# EFR32MG24A111F1536GM48 register map
Vendor: Silicon Labs; Series: EFR32; File version: B
Registers are 32-bit, read-write, reset 0x0 unless marked. A register's access mark holds for its fields unless they carry their own. Offsets are from the block's base; [hi:lo] are bit positions; {n}, {i} and the like mark numbered series; 'fields as' and 'values as' point back to an identical list.

## SYNTH_S — SYNTH_S Registers
Base 0xA8018000
Same registers: SYNTH_NS 0xB8018000
0x00 IPVERSION ro reset 0x2
0x04 EN
  [0] EN — Enable peripheral clock to this module
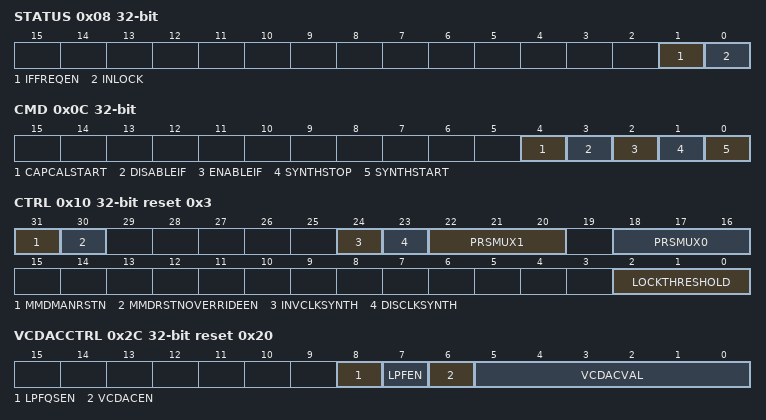
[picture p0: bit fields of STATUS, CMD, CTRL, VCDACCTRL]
0x08 STATUS ro
  [1] IFFREQEN — Synthesizer IF frequency enable status
  [0] INLOCK — RF Synthesizer in Lock
0x0C CMD wo
  [4] CAPCALSTART — Start VCO capacitor array calibration
  [3] DISABLEIF — Disable the synthesizer IF frequency
  [2] ENABLEIF — Enable the synthesizer IF frequency
  [1] SYNTHSTOP — Stops the RF synthesizer
  [0] SYNTHSTART — Starts the RF synthesizer
0x10 CTRL reset 0x3
  [31] MMDMANRSTN — Manual MMD reset
    0=RESET (Reset MMD and DSM logic); 1=NORESET (Allow MMD and DSM to run)
  [30] MMDRSTNOVERRIDEEN — Enable MMD reset override
    0=DISABLE (Disable MMD reset override); 1=ENABLE (Enable MMD reset override)
  [24] INVCLKSYNTH — Invert clk_synth
    0=NO (Do not invert clk_synth); 1=YES (Invert clk_synth)
  [23] DISCLKSYNTH — Disable clk_synth
    0=ENABLE (Enable clk_synth); 1=DISABLE (Disable clk_synth)
  [22:20] PRSMUX1 — PRS output mux 1 selector
    0=DISABLED (PRS output 1 is disabled); 1=AUXINLOCK (Obsolete. read returns 0.); 2=REF_IS_LEADING (Disabled. Read returns 0.); 3=FPLL (Divided PLL clock); 4=VCCMP_LOW (VCO voltage low detected); 5=MMD_PRESCALER_RESET_N (MMD prescaler reset, active low); 6=CLK_SYNTH_DIV2 (MMD next denom output, corresponding to the delta-sigma clock, divided by 2.)
  [18:16] PRSMUX0 — PRS output mux 0 selector
    0=DISABLED (PRS output 0 is disabled); 1=INLOCK (Synthesizer is in lock); 2=LOCK_WINDOW (PLL Lock Window, sampled by PFD); 3=FPLL (Divided PLL clock); 4=VCCMP_HI (VCO voltage high detected); 5=VCO_AMPLITUDE_OK (Obsolete. Read returns 1.); 6=VCO_DET_OUT_D (Obsolete. Read returns 0.)
  [2:0] LOCKTHRESHOLD — Frequency synthesizer lock threshold
0x2C VCDACCTRL reset 0x20
  [8] LPFQSEN — LPF Quickstart Control
    0=DISABLE (Disable LPF); 1=ENABLE (Enable LPF)
  [7] LPFEN — LPF Enable Control
    0=DISABLE (Disable LPF); 1=ENABLE (Enable LPF)
  [6] VCDACEN — Enable VCDAC
    0=DISABLE (VC DAC disabled); 1=ENABLE (VC DAC enabled)
  [5:0] VCDACVAL — Control voltage to VCO
0x34 FREQ
  [27:0] FREQ — RF Carrier Frequency.
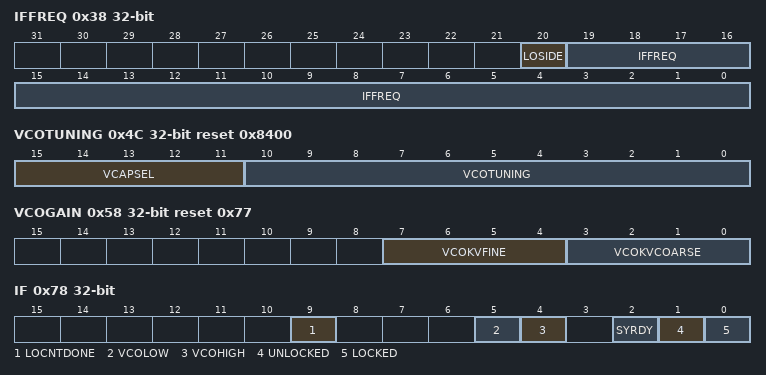
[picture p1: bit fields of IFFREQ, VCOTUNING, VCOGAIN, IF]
0x38 IFFREQ
  [20] LOSIDE — Configure LO in receive
    0=LOW (The local oscillator (LO) is lower in frequency than the receive RF channel. In MODEM_MIXCTRL the ANAMIXMODE field must be set to NORMAL and DIGIQSWAPEN must be cleared.); 1=HIGH (The local oscillator (LO) is higher in frequency than the receive RF channel. In MODEM_MIXCTRL the ANAMIXMODE field must be set to CONJUGATE and DIGIQSWAPEN must be set.)
  [19:0] IFFREQ — IF used in receive mode
0x3C DIVCTRL reset 0x1
  [8:0] LODIVFREQCTRL — Frequency division
    {v}=LODIV{v} (Divide LO frequency by {v}.) (v=1..5); 7=LODIV7 (Divide LO frequency by 7.); 19=LODIV6 (Divide LO frequency by 6.); 20=LODIV8 (Divide LO frequency by 8.); 21=LODIV10 (Divide LO frequency by 10.); 23=LODIV14 (Divide LO frequency by 14.); 27=LODIV9 (Divide LO frequency by 9.); 28=LODIV12 (Divide LO frequency by 12.); 29=LODIV15 (Divide LO frequency by 15.); 36=LODIV16 (Divide LO frequency by 16.); 37=LODIV20 (Divide LO frequency by 20.); 155=LODIV18 (Divide LO frequency by 18.); 156=LODIV24 (Divide LO frequency by 24.)
0x40 CHCTRL
  [5:0] CHNO — Channel number
0x44 CHSP
  [17:0] CHSP — Channel spacing
0x48 CALOFFSET
  [14:0] CALOFFSET — Carrier calibration offset
0x4C VCOTUNING reset 0x8400
  [15:11] VCAPSEL — VCO varactor cap select
  [10:0] VCOTUNING — VCO capacitor array calibration value.
0x58 VCOGAIN reset 0x77
  [7:4] VCOKVFINE — VCO varactor fine gain setting
  [3:0] VCOKVCOARSE — VCO varactor coarse gain setting
0x78 IF
  [9] LOCNTDONE — LOCNT measurement done Interrupt Flag
  [5] VCOLOW — VCO low voltage Interrupt Flag
  [4] VCOHIGH — VCO high voltage Interrupt Flag
  [2] SYRDY — Synthesizer ready Interrupt Flag
  [1] UNLOCKED — Synthesizer unlocked Interrupt Flag
  [0] LOCKED — Synthesizer locked Interrupt Flag
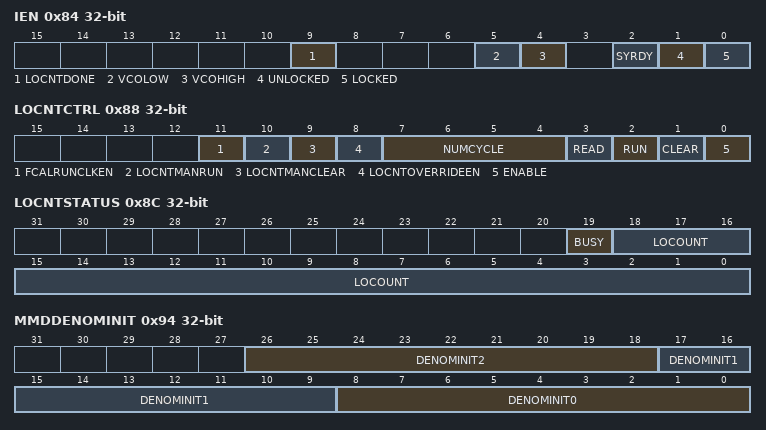
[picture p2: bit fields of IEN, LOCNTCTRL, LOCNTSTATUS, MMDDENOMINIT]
0x84 IEN
  [9] LOCNTDONE — LOCNTDONE Interrupt Enable
  [5] VCOLOW — VCOLOW Interrupt Enable
  [4] VCOHIGH — VCOHIGH Interrupt Enable
  [2] SYRDY — CAPCALDONE Interrupt Enable
  [1] UNLOCKED — UNLOCKED Interrupt Enable
  [0] LOCKED — LOCKED Interrupt Enable
0x88 LOCNTCTRL
  [11] FCALRUNCLKEN — Enable FCAL run pulse counter clock
    0=DISABLE (Don't enable clock); 1=ENABLE (Enable clock)
  [10] LOCNTMANRUN — Manual Control of the LO counter RUN
    0=NORUN (Don't initiate start/stop LO counter); 1=RUN (Initiate start/stop of LO counter)
  [9] LOCNTMANCLEAR — Manual Control of LO counter CLEAR
    0=NOCLEAR (Don't clear LO counter); 1=CLEAR (Clear LO counter)
  [8] LOCNTOVERRIDEEN — Enable manual override of CLEAR and RUN
    0=DISABLE (Disable manual override); 1=ENABLE (Enable manual override)
  [7:4] NUMCYCLE — Number of Clock Cycles to Run LO Counter
    0=CNT_2 (Set count length to 2 XO clock cycles); 1=CNT_4 (Set count length to 4 XO clock cycles); 2=CNT_8 (Set count length to 8 XO clock cycles); 3=CNT_16 (Set count length to 16 XO clock cycles); 4=CNT_32 (Set count length to 32 XO clock cycles); 5=CNT_64 (Set count length to 64 XO clock cycles); 6=CNT_128 (Set count length to 128 XO clock cycles); 7=CNT_256 (Set count length to 256 XO clock cycles); 8=CNT_512 (Set count length to 512 XO clock cycles); 9=CNT_1024 (Set count length to 1024 XO clock cycles); 10=CNT_2048 (Set count length to 2048 XO clock cycles); 11=CNT_4096 (Set count length to 4096 XO clock cycles); 12=CNT_8192 (Set count length to 8192 XO clock cycles)
  [3] READ — Read LO Counter
    0=OFF (LOCOUNT register read returns all 0's); 1=ON (LOCOUNT register read returns count value)
  [2] RUN wo — Run LO Counter
    0=OFF (Do not run LO counter); 1=ON (Run LO counter)
  [1] CLEAR wo — Clear LO Counter
    0=OFF (Do not clear LO counter); 1=ON (Clear LO counter)
  [0] ENABLE — Enable LO Counter
    0=OFF (LO counter is disabled); 1=ON (LO counter is enabled)
0x8C LOCNTSTATUS ro
  [19] BUSY — LO Counter is Busy
  [18:0] LOCOUNT — LO Counter Value
0x90 LOCNTTARGET ro
  [18:0] TARGET — LO Counter Measurement Target
0x94 MMDDENOMINIT
  [26:18] DENOMINIT2 — Initial mmd_denom value 2
  [17:9] DENOMINIT1 — Initial mmd_denom value 1
  [8:0] DENOMINIT0 — Initial mmd_denom value 0
0x98 CHPDACINIT
  [11:0] DACINIT — Initial CHP DAC Value
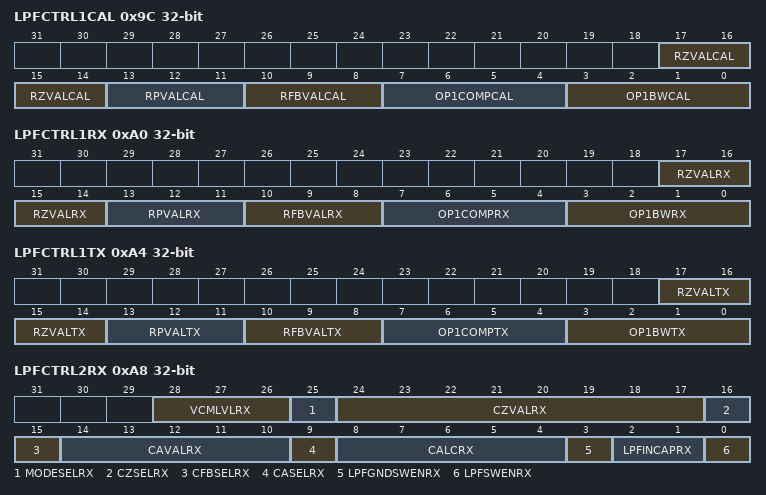
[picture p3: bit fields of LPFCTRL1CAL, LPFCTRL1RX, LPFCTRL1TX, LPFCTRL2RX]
0x9C LPFCTRL1CAL
  [17:14] RZVALCAL — LPF Rz Value Select in Cal Mode
  [13:11] RPVALCAL — LPF Rp Value Select in Cal Mode
  [10:8] RFBVALCAL — LPF Rfb Value Select in Cal Mode
  [7:4] OP1COMPCAL — LPF Op1 Comp Control in Cal Mode
  [3:0] OP1BWCAL — LPF Op1 BW Control in Cal Mode
0xA0 LPFCTRL1RX
  [17:14] RZVALRX — LPF Rz Value Select in RX Mode
  [13:11] RPVALRX — LPF Rp Value Select in RX Mode
  [10:8] RFBVALRX — LPF Rfb Value Select in RX Mode
  [7:4] OP1COMPRX — LPF Op1 Comp Control in RX Mode
  [3:0] OP1BWRX — LPF Op1 BW Control in RX Mode
0xA4 LPFCTRL1TX
  [17:14] RZVALTX — LPF Rz Value Select in TX Mode
  [13:11] RPVALTX — LPF Rp Value Select in TX Mode
  [10:8] RFBVALTX — LPF Rfb Value Select in TX Mode
  [7:4] OP1COMPTX — LPF Op1 Comp Control in TX Mode
  [3:0] OP1BWTX — LPF Op1 BW Control in TX Mode
0xA8 LPFCTRL2RX
  [28:26] VCMLVLRX — LPF Vcm Level Select in RX Mode
  [25] MODESELRX — LPF Filter Mode Select in RX Mode
    0=ONEOP (Sets 1 opamp configuration); 1=TWOOP (Sets 2 opamp configuration)
  [24:17] CZVALRX — LPF Cz Value Select in RX Mode
  [16] CZSELRX — LPF Cz Select in RX Mode
    0=DISABLE (Disable Cz); 1=ENABLE (Enable Cz)
  [15] CFBSELRX — LPF Cfb Select in RX Mode
    0=DISABLE (Disable Cfb); 1=ENABLE (Enable Cfb)
  [14:10] CAVALRX — LPF Ca Value Select in RX Mode
  [9] CASELRX — LPF Ca Select in RX Mode
    0=DISABLE (Disable Ca); 1=ENABLE (Enable Ca)
  [8:4] CALCRX — LPF Cap Cal Select in RX Mode
  [3] LPFGNDSWENRX — LPF Gnd Switch Enable in RX Mode
    0=DISABLE (Disable GND switching); 1=ENABLE (Enable GND switching)
  [2:1] LPFINCAPRX — LPF Input Cap Select in RX Mode
  [0] LPFSWENRX — LPF Switching Enable in RX Mode
    0=DISABLE (Disable switching); 1=ENABLE (Enable switching)
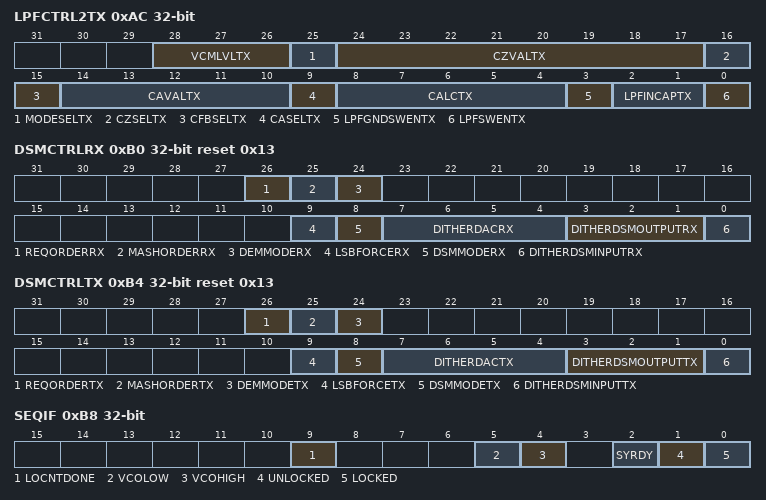
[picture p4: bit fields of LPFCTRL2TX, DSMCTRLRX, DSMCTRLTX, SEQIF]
0xAC LPFCTRL2TX
  [28:26] VCMLVLTX — LPF Vcm Level Select in TX Mode
  [25] MODESELTX — LPF Filter Mode Select in TX Mode
    0=ONEOP (1 opamp configuration); 1=TWOOP (2 opamp configuration)
  [24:17] CZVALTX — LPF Cz Value Select in TX Mode
  [16] CZSELTX — LPF Cz Select in TX Mode
    0=DISABLE (Disable Cz); 1=ENABLE (Enable Cz)
  [15] CFBSELTX — LPF Cfb Select in TX Mode
    0=DISABLE (Disable Cfb); 1=ENABLE (Enable Cfb)
  [14:10] CAVALTX — LPF Ca Value Select in TX Mode
  [9] CASELTX — LPF Ca Select in TX Mode
    0=DISABLE (Disable Ca); 1=ENABLE (Enable Ca)
  [8:4] CALCTX — LPF Cap Cal Select in TX Mode
  [3] LPFGNDSWENTX — LPF Gnd Switch Enable in TX Mode
    values as LPFCTRL2RX.LPFGNDSWENRX
  [2:1] LPFINCAPTX — LPF Input Cap Select in TX Mode
  [0] LPFSWENTX — LPF Switching Enable in TX Mode
    0=DISABLE (Disable switching); 1=ENABLE (Enable switching)
0xB0 DSMCTRLRX reset 0x13
  [26] REQORDERRX — ReQuant order for RX mode
    0=FIRST (1st Order DAC); 1=SECOND (2rd Order DAC)
  [25] MASHORDERRX — MASH order for RX mode
    0=SECOND (2nd Order Mash); 1=THIRD (3rd Order Mash)
  [24] DEMMODERX — DEM Mode for RX mode
    0=DISABLED (DEM is disabled); 1=ENABLED (DEM is enabled)
  [9] LSBFORCERX — Delta-sigma input force LSB for RX mode
  [8] DSMMODERX — Delta-sigma topology for RX mode
    0=FEEDFORWARD (Feed forward architecture); 1=MASH (MASH architecture. Note that the delta-sigma output dithering (DITHERDSMOUTPUT) is not available in this mode.)
  [7:4] DITHERDACRX — Dithering of charge pump DAC for RX mode
  [3:1] DITHERDSMOUTPUTRX — Dithering of DSM output for RX mode
  [0] DITHERDSMINPUTRX — Dithering of DSM input for RX mode
0xB4 DSMCTRLTX reset 0x13
  [26] REQORDERTX — ReQuant order for TX mode
    0=FIRST (1st Order DAC); 1=SECOND (2rd Order DAC)
  [25] MASHORDERTX — MASH order for TX mode
    0=SECOND (2nd Order Mash); 1=THIRD (3rd Order Mash)
  [24] DEMMODETX — DEM Mode for TX mode
    0=DISABLED (DEM is disabled); 1=ENABLED (DEM is enabled)
  [9] LSBFORCETX — Delta-sigma input force LSB for TX mode
  [8] DSMMODETX — Delta-sigma topology for TX mode
    values as DSMCTRLRX.DSMMODERX
  [7:4] DITHERDACTX — Dithering of charge pump DAC for TX mode
  [3:1] DITHERDSMOUTPUTTX — Dithering of DSM output for TX mode
  [0] DITHERDSMINPUTTX — Dithering of DSM input for TX mode
0xB8 SEQIF
  fields as IF
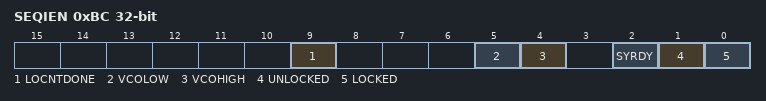
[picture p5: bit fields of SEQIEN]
0xBC SEQIEN
  fields as IEN
